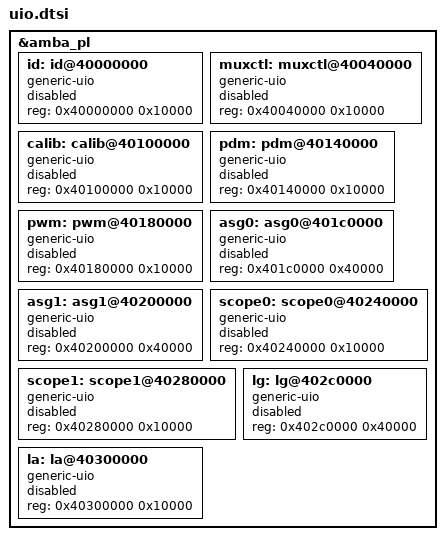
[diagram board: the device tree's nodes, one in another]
/*
 * Add UIO peripherals
 */

&amba_pl {
	id: id@40000000 {
		compatible = "generic-uio";
		reg = <0x40000000 0x10000>;
		status = "disabled";
	};
	muxctl: muxctl@40040000 {
		compatible = "generic-uio";
		reg = <0x40040000 0x10000>;
		status = "disabled";
	};
	calib: calib@40100000 {
		compatible = "generic-uio";
		reg = <0x40100000 0x10000>;
		status = "disabled";
	};
	pdm: pdm@40140000 {
		compatible = "generic-uio";
		reg = <0x40140000 0x10000>;
		status = "disabled";
	};
	pwm: pwm@40180000 {
		compatible = "generic-uio";
		reg = <0x40180000 0x10000>;
		status = "disabled";
	};
	asg0: asg0@401c0000 {
		compatible = "generic-uio";
		reg = <0x401c0000 0x40000>;
		status = "disabled";
	};
	asg1: asg1@40200000 {
		compatible = "generic-uio";
		reg = <0x40200000 0x40000>;
		status = "disabled";
	};
	scope0: scope0@40240000 {
		compatible = "generic-uio";
		reg = <0x40240000 0x10000>;
		status = "disabled";
	};
	scope1: scope1@40280000 {
		compatible = "generic-uio";
		reg = <0x40280000 0x10000>;
		status = "disabled";
	};
	lg: lg@402c0000 {
		compatible = "generic-uio";
		reg = <0x402c0000 0x40000>;
		status = "disabled";
	};
	la: la@40300000 {
		compatible = "generic-uio";
		reg = <0x40300000 0x10000>;
		status = "disabled";
	};
};
